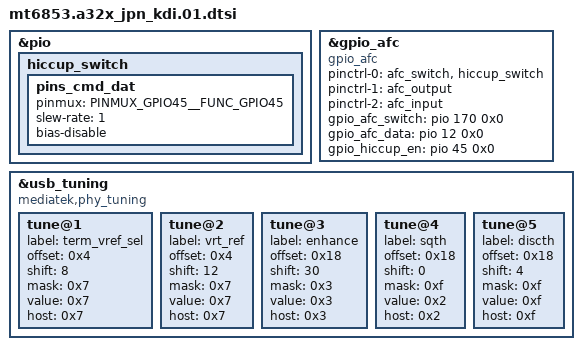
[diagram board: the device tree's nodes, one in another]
/*
 * Generated by Samsung
 * If these files should be changed, then please make a sync with MTK
*/

#include "../../mediatek/k6853v1_64_titan/gpio01_jpn.dtsi"
#include "mt6853-a32x_common.dtsi"
#include "mt6853-a32x_camera_03.dtsi"
#include "mt6853-a32x_jpn_gripsensor_00.dtsi"
#include "display_lcd_a32x_common.dtsi"
#include "mt6853_input_a32x_05.dtsi"

&pio {
	hiccup_switch: hiccup_switch {
		pins_cmd_dat {
			pinmux = <PINMUX_GPIO45__FUNC_GPIO45>;
			slew-rate = <1>;
			bias-disable;
		};
	};
};

&gpio_afc {
	compatible = "gpio_afc";
	pinctrl-names = "default", "output", "input";
	pinctrl-0 = <&afc_switch &hiccup_switch>;
	pinctrl-1 = <&afc_output>;
	pinctrl-2 = <&afc_input>;
	status = "okay";
	gpio_afc_switch = <&pio 170 0x0>;
	gpio_afc_data = <&pio 12 0x0>;
	gpio_hiccup_en = <&pio 45 0x0>;
};

&usb_tuning {
	compatible = "mediatek,phy_tuning";

	tune@1 {
		label = "term_vref_sel";
		offset = <0x4>;
		shift = <8>;
		mask = <0x7>;
		value = <0x7>;
		host = <0x7>;
	};

	tune@2 {
		label = "vrt_ref";
		offset = <0x4>;
		shift = <12>;
		mask = <0x7>;
		value = <0x7>;
		host = <0x7>;
	};

	tune@3 {
		label = "enhance";
		offset = <0x18>;
		shift = <30>;
		mask = <0x3>;
		value = <0x3>;
		host = <0x3>;
	};

	tune@4 {
		label = "sqth";
		offset = <0x18>;
		shift = <0>;
		mask = <0xf>;
		value = <0x2>;
		host = <0x2>;
	};

	tune@5 {
		label = "discth";
		offset = <0x18>;
		shift = <4>;
		mask = <0xf>;
		value = <0xf>;
		host = <0xf>;
	};
};

/*End of this file, DO NOT ADD ANYTHING HERE*/
